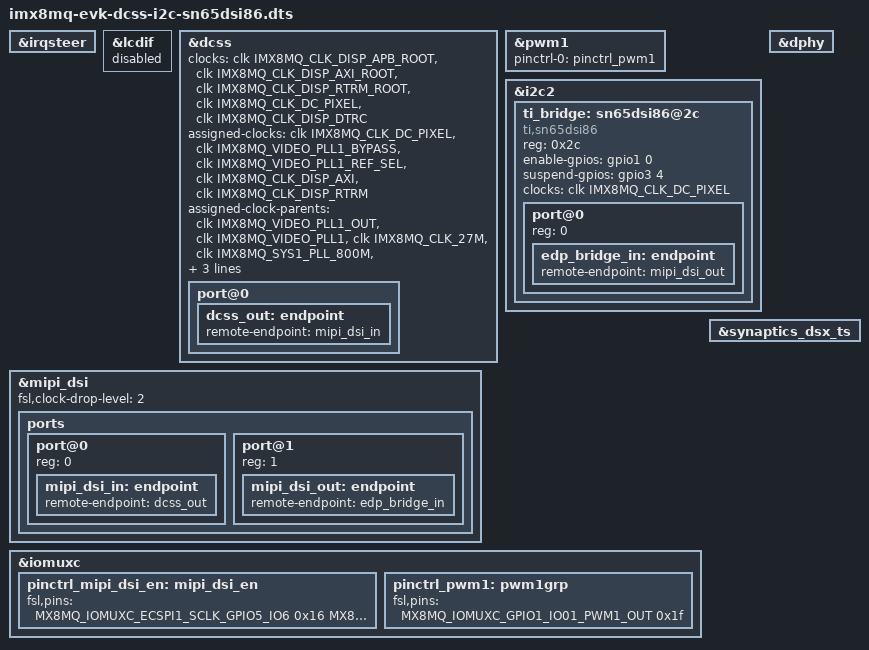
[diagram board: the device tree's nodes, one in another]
// SPDX-License-Identifier: GPL-2.0
/*
 * Copyright 2019 NXP.
 */

#include "imx8mq-evk.dts"

/delete-node/&hdmi;

&irqsteer {
	status = "okay";
};

&lcdif {
	status = "disabled";
};

&dcss {
	status = "okay";

	clocks = <&clk IMX8MQ_CLK_DISP_APB_ROOT>,
		 <&clk IMX8MQ_CLK_DISP_AXI_ROOT>,
		 <&clk IMX8MQ_CLK_DISP_RTRM_ROOT>,
		 <&clk IMX8MQ_CLK_DC_PIXEL>,
		 <&clk IMX8MQ_CLK_DISP_DTRC>;
	clock-names = "apb", "axi", "rtrm", "pix", "dtrc";
	assigned-clocks = <&clk IMX8MQ_CLK_DC_PIXEL>,
					  <&clk IMX8MQ_VIDEO_PLL1_BYPASS>,
					  <&clk IMX8MQ_VIDEO_PLL1_REF_SEL>,
					  <&clk IMX8MQ_CLK_DISP_AXI>,
					  <&clk IMX8MQ_CLK_DISP_RTRM>;
	assigned-clock-parents = <&clk IMX8MQ_VIDEO_PLL1_OUT>,
							 <&clk IMX8MQ_VIDEO_PLL1>,
							 <&clk IMX8MQ_CLK_27M>,
							 <&clk IMX8MQ_SYS1_PLL_800M>,
							 <&clk IMX8MQ_SYS1_PLL_800M>;
	assigned-clock-rates = <600000000>, <0>, <0>,
						   <800000000>,
						   <400000000>;

	port@0 {
		dcss_out: endpoint {
			remote-endpoint = <&mipi_dsi_in>;
		};
	};
};

&pwm1 {                                                                         
        status = "okay";
	pinctrl-names = "default";
	pinctrl-0 = <&pinctrl_pwm1>;			
};


&i2c2 {

	ti_bridge: sn65dsi86@2c {
		compatible = "ti,sn65dsi86";
		#address-cells = <1>;
		#size-cells = <0>;
		reg = <0x2c>;
		enable-gpios = <&gpio1 0 GPIO_ACTIVE_HIGH>;
		suspend-gpios = <&gpio3 4 GPIO_ACTIVE_HIGH>;

		clock-names = "refclk";
		clocks = <&clk IMX8MQ_CLK_DC_PIXEL>; 
		status = "okay";

		port@0{
			reg = <0>; 
			edp_bridge_in: endpoint {
				remote-endpoint = <&mipi_dsi_out>;
			};
		};		
	};

};


&mipi_dsi {
	status = "okay";
	fsl,clock-drop-level = <2>;

	ports {
		#address-cells = <1>;
		#size-cells = <0>;

		port@0 {
			reg = <0>;
			mipi_dsi_in: endpoint {
				remote-endpoint = <&dcss_out>;
			};
		};

		port@1 {
			reg = <1>;
			mipi_dsi_out: endpoint {
				remote-endpoint = <&edp_bridge_in>;
			};
		};
	};
};

&dphy {
	status = "okay";
};

&iomuxc {
	pinctrl_mipi_dsi_en: mipi_dsi_en {
		fsl,pins = <
			MX8MQ_IOMUXC_ECSPI1_SCLK_GPIO5_IO6	0x16
			MX8MQ_IOMUXC_GPIO1_IO00_GPIO1_IO0	0x16  /*reset*/
			MX8MQ_IOMUXC_NAND_CE2_B_GPIO3_IO3	0x16  /*blk en*/
			MX8MQ_IOMUXC_NAND_CE3_B_GPIO3_IO4	0x16 /*power en */
			MX8MQ_IOMUXC_SAI2_RXC_GPIO4_IO22	0x16 /*STBY*/
		>;
	};

	pinctrl_pwm1: pwm1grp {
		fsl,pins = <
			MX8MQ_IOMUXC_GPIO1_IO01_PWM1_OUT        0x1f   /*pwm*/
		>;
	};		
};

&synaptics_dsx_ts {
	status = "okay";
};
